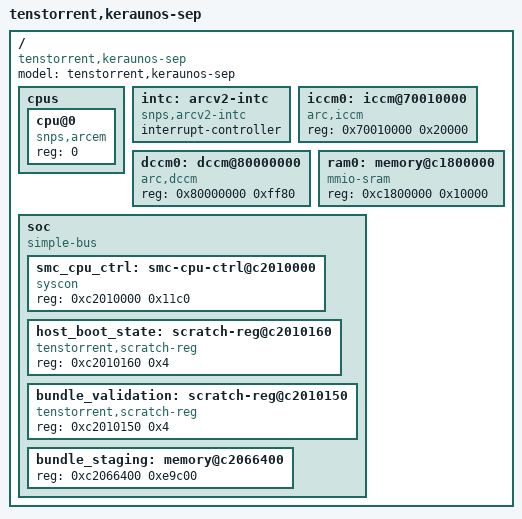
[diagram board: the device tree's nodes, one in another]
/*
 * Copyright (c) 2026 Tenstorrent AI ULC
 *
 * SPDX-License-Identifier: Apache-2.0
 */

#include "skeleton.dtsi"

/ {
	compatible = "tenstorrent,keraunos-sep";
	model = "tenstorrent,keraunos-sep";

	cpus {
		#address-cells = <1>;
		#size-cells = <0>;

		cpu@0 {
			device_type = "cpu";
			compatible = "snps,arcem";
			reg = <0>;
		};
	};

	intc: arcv2-intc {
		compatible = "snps,arcv2-intc";
		interrupt-controller;
		#interrupt-cells = <2>;
	};

	/* BL0 copies BL1 to the start of ICCM SRAM and jumps there. */
	iccm0: iccm@70010000 {
		compatible = "arc,iccm";
		reg = <0x70010000 0x20000>;
	};

	/* Stops 0x80 short of the 64 KiB DCCM: BL0 leaves its handoff struct at
	 * the end of DCCM for BL1 to walk back from.
	 */
	dccm0: dccm@80000000 {
		compatible = "arc,dccm";
		reg = <0x80000000 0xff80>;
	};

	/* RoT extension scratch pad, also the window shared with the system. */
	ram0: memory@c1800000 {
		compatible = "mmio-sram";
		reg = <0xc1800000 0x10000>;
	};

	soc {
		#address-cells = <1>;
		#size-cells = <1>;
		compatible = "simple-bus";
		ranges;

		smc_cpu_ctrl: smc-cpu-ctrl@c2010000 {
			compatible = "syscon";
			reg = <0xc2010000 0x11c0>;
			status = "okay";
		};

		host_boot_state: scratch-reg@c2010160 {
			compatible = "tenstorrent,scratch-reg";
			reg = <0xc2010160 0x4>;
			status = "okay";
		};

		bundle_validation: scratch-reg@c2010150 {
			compatible = "tenstorrent,scratch-reg";
			reg = <0xc2010150 0x4>;
			status = "okay";
		};

		/* BUN1 then BUN2, up to the SRAM SMC BL0P5 runs from */
		bundle_staging: memory@c2066400 {
			reg = <0xc2066400 0xe9c00>;
			status = "okay";
		};
	};
};
